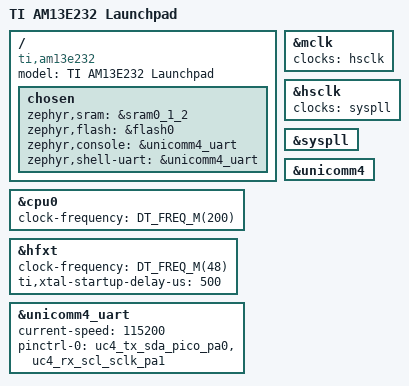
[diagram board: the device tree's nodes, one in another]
/*
 * Copyright (c) 2026 Texas Instruments Incorporated
 *
 * SPDX-License-Identifier: Apache-2.0
 */

/dts-v1/;

#include <ti/am13/am13e232.dtsi>
#include <ti/am13/am13e23019-pinctrl.dtsi>
#include <zephyr/dt-bindings/gpio/gpio.h>
#include <zephyr/dt-bindings/input/input-event-codes.h>
#include <zephyr/dt-bindings/mux/ti_am13e2_xbar_in.h>
#include <zephyr/dt-bindings/mux/ti_am13e2_xbar_out.h>

/ {
	model = "TI AM13E232 Launchpad";
	compatible = "ti,am13e232";

	chosen {
		zephyr,sram = &sram0_1_2;
		zephyr,flash = &flash0;
		zephyr,console = &unicomm4_uart;
		zephyr,shell-uart = &unicomm4_uart;
	};
};

&cpu0 {
	clock-frequency = <DT_FREQ_M(200)>;
};

&mclk {
	clocks = <&hsclk>;
};

&hsclk {
	clocks = <&syspll>;
	status = "okay";
};

&syspll {
	status = "okay";
};

&hfxt {
	clock-frequency = <DT_FREQ_M(48)>;
	ti,xtal-startup-delay-us = <500>;
};

&unicomm4 {
	status = "okay";
};

&unicomm4_uart {
	status = "okay";
	current-speed = <115200>;
	pinctrl-0 = <&uc4_tx_sda_pico_pa0 &uc4_rx_scl_sclk_pa1>;
	pinctrl-names = "default";
};
